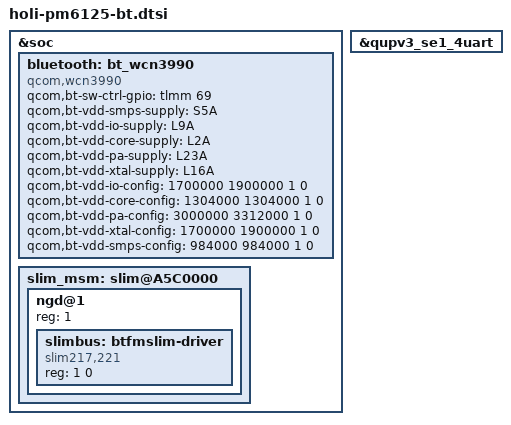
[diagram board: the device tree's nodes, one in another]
#include <dt-bindings/interconnect/qcom,holi.h>

&soc {
	bluetooth: bt_wcn3990 {
		compatible = "qcom,wcn3990";
		qcom,bt-sw-ctrl-gpio = <&tlmm 69 0>;
		qcom,bt-vdd-smps-supply = <&S5A>;  /* SMPS */
		qcom,bt-vdd-io-supply = <&L9A>;  /* IO */
		qcom,bt-vdd-core-supply = <&L2A>; /* RFA */
		qcom,bt-vdd-pa-supply = <&L23A>; /* CH0 */
		qcom,bt-vdd-xtal-supply = <&L16A>; /* XO */

		qcom,bt-vdd-io-config = <1700000 1900000 1 0>;
		qcom,bt-vdd-core-config = <1304000 1304000 1 0>;
		qcom,bt-vdd-pa-config = <3000000 3312000 1 0>;
		qcom,bt-vdd-xtal-config = <1700000 1900000 1 0>;
		qcom,bt-vdd-smps-config = <984000 984000 1 0>;
	};

	slim_msm: slim@A5C0000 {
		status =  "ok";
		ngd@1 {
			reg = <1>;
			#address-cells = <1>;
			#size-cells = <1>;
			//slimbus child nodes
			slimbus: btfmslim-driver {
				compatible = "slim217,221";
				reg = <1 0>;
			};
		};
	};
};

//uart instance
&qupv3_se1_4uart {
       status = "ok";
};
